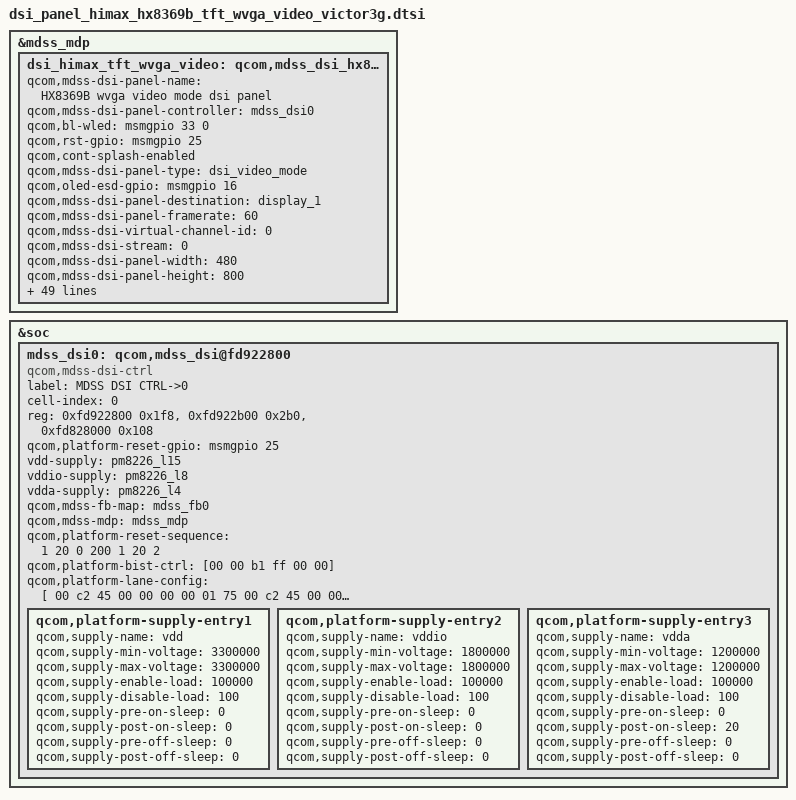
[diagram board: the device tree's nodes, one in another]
/* Copyright (c) 2012, Samsung Electronics Corporation. All rights reserved.
 *
 * This program is free software; you can redistribute it and/or modify
 * it under the terms of the GNU General Public License version 2 and
 * only version 2 as published by the Free Software Foundation.
 *
 * This program is distributed in the hope that it will be useful,
 * but WITHOUT ANY WARRANTY; without even the implied warranty of
 * MERCHANTABILITY or FITNESS FOR A PARTICULAR PURPOSE.  See the
 * GNU General Public License for more details.
 */

&mdss_mdp {

	dsi_himax_tft_wvga_video: qcom,mdss_dsi_hx8369b_wvga_video {
		qcom,mdss-dsi-panel-name = "HX8369B wvga video mode dsi panel";
		qcom,mdss-dsi-panel-controller = <&mdss_dsi0>;
		qcom,bl-wled = <&msmgpio 33 0>;
                qcom,rst-gpio = <&msmgpio 25 0>;
                qcom,cont-splash-enabled;
		qcom,mdss-dsi-panel-type = "dsi_video_mode";
		qcom,oled-esd-gpio = <&msmgpio 16 0>;
		qcom,mdss-dsi-panel-destination = "display_1";
		qcom,mdss-dsi-panel-framerate = <60>;
		qcom,mdss-dsi-virtual-channel-id = <0>;
		qcom,mdss-dsi-stream = <0>;
		qcom,mdss-dsi-panel-width = <480>;
		qcom,mdss-dsi-panel-height = <800>;
                qcom,mdss-pan-physical-width-dimension = <60>; /* <Width> real size of panel in mm */
		qcom,mdss-pan-physical-height-dimension = <100>; /*<Height> real size of panel in mm */
		qcom,mdss-dsi-lp11-init;
		qcom,mdss-dsi-init-delay-us = <100>;
		qcom,mdss-dsi-h-front-porch = <146>;
		qcom,mdss-dsi-h-back-porch = <136>;
		qcom,mdss-dsi-h-pulse-width = <60>;
		qcom,mdss-dsi-h-sync-skew = <0>;
		qcom,mdss-dsi-v-back-porch = <9>;
		qcom,mdss-dsi-v-front-porch = <10>;
		qcom,mdss-dsi-v-pulse-width = <6>;
		qcom,mdss-dsi-h-left-border = <0>;
		qcom,mdss-dsi-h-right-border = <0>;
		qcom,mdss-dsi-v-top-border = <0>;
		qcom,mdss-dsi-v-bottom-border = <0>;
		qcom,mdss-dsi-bpp = <24>;
		qcom,mdss-dsi-color-order = <0>;
		qcom,mdss-dsi-underflow-color = <0xff>;
		qcom,mdss-dsi-border-color = <0>;
		qcom,mdss-dsi-mdp-trigger = <0x0>;
		qcom,mdss-dsi-dma-trigger = <0x04>;
		qcom,mdss-dsi-bl-min-level = <1>;
		qcom,mdss-dsi-bl-max-level = <255>;
		qcom,mdss-dsi-bl-pmic-control-type = "bl_ctrl_pwm";
		qcom,mdss-pan-dsi-t-clk-pre = <0x18>;
		qcom,mdss-pan-dsi-t-clk-post = <0x04>;
		qcom,mdss-dsi-lane-0-state;
		qcom,mdss-dsi-lane-1-state;
		qcom,mdss-dsi-bllp-eof-power-mode;
		qcom,mdss-dsi-bllp-power-mode;
		qcom,mdss-dsi-traffic-mode = <2>;
		qcom,mdss-force-clk-lane-hs = <1>;
		qcom,mdss-dsi-lane-map = <5>;
		qcom,mdss-dsi-h-sync-pulse = <0>;
		qcom,mdss-dsi-panel-clock-rate = <489000000>;		
                qcom,mdss-dsi-panel-timings = [33 1E 14 00 44 48 18 22 19 03 04 00];
		qcom,platform-strength-ctrl = [ff 06];
		qcom,platform-regulator-settings = [07 08 07 00 20 07 01];
		qcom,mdss-dsi-on-command = [39 01 00 00 01 00 04 B9 FF 83 69
					39 01 00 00 0A 00 10 BA 31 00 16 CA B1 0A 00 10 28 02 21 21 9A 1A 8F
					39 01 00 00 01 00 02 3A 70
					39 01 00 00 01 00 5D D5 
					00 00 01 00 03 00 00 18 01 00 00 00 01 60 37 
					00 00 03 07 08 47 00 00 00 60 00 00 00 00 00
					00 00 03 00 00 10 00 00 91 13 35 57 75 18 00 
					00 00 86 64 42 20 00 49 00 00 00 90 02 24 46 
					64 08 00 00 00 87 75 53 31 11 59 00 00 00 00 
					01 00 00 00 0F 00 0F FF FF 0F 00 0F FF FF 00 
					85 5A
					39 01 00 00 01 00 0B B1 0B 83 77 00 0F 0F 17 17 0C 1A
					39 01 00 00 01 00 05 B3 83 00 31 03
               				39 01 00 00 01 00 02 B4 00
               				39 01 00 00 01 00 02 CB 6D
					39 01 00 00 01 00 02 CC 0E
					39 01 00 00 01 00 02 C1 00
					39 01 00 00 01 00 05 C6 41 FF 7A FF
					39 01 00 00 01 00 02 EA 72
					39 01 00 00 01 00 05 E3 07 0F 07 0F
               				39 01 00 00 78 00 07 C0 73 50 00 34 C4 09
               				39 01 00 00 01 00 24 E0 01 0E 12 29 2D 30 1E 3B 08 0D 0F 13 15 13 14 10 16 01 0E 11 2A 2D 30 1D 3B 08 0D 0F 13 15
                                        13 14 0F 16 01
               				05 01 00 00 B4 00 02 11 00
					05 01 00 00 01 00 02 29 00
	/* Display On */
					];
		samsung,panel-manufacture-id-read-cmds = [06 01 00 00 00 00 01 da 01
							06 01 00 00 00 00 01 db 01
							06 01 00 00 00 00 01 dc 01];

		qcom,mdss-dsi-on-command-state = "dsi_lp_mode";
		qcom,mdss-dsi-off-command = [05 01 00 00 32 00 02 28 00
					05 01 00 00 78 00 02 10 00];
		qcom,mdss-dsi-off-command-state = "dsi_hs_mode";
	};
};

&soc {
	mdss_dsi0: qcom,mdss_dsi@fd922800 {
		compatible = "qcom,mdss-dsi-ctrl";
		label = "MDSS DSI CTRL->0";
		cell-index = <0>;
		reg = 	<0xfd922800 0x1f8>,
			<0xfd922b00 0x2b0>,
			<0xfd828000 0x108>;
		reg-names = "dsi_ctrl", "dsi_phy", "mmss_misc_phys";
		qcom,platform-reset-gpio = <&msmgpio 25 0>;
		vdd-supply = <&pm8226_l15>;
		vddio-supply = <&pm8226_l8>;
		vdda-supply = <&pm8226_l4>;
		qcom,mdss-fb-map = <&mdss_fb0>;
		qcom,mdss-mdp = <&mdss_mdp>;
		qcom,platform-reset-sequence = <1 20 0 200 1 20 2>;
		qcom,platform-bist-ctrl = [00 00 b1 ff 00 00];
		qcom,platform-lane-config = [
			00 c2 45 00 00 00 00 01 75 /* lane0 config */
			00 c2 45 00 00 00 00 01 75 /* lane1 config */
			00 c2 45 00 00 00 00 01 75 /* lane2 config */
			00 c2 45 00 00 00 00 01 75 /* lane3 config */
			00 02 45 00 00 00 00 01 97]; /* Clk ln config */
		qcom,platform-supply-entry1 {
			qcom,supply-name = "vdd";
			qcom,supply-min-voltage = <3300000>;
			qcom,supply-max-voltage = <3300000>;
			qcom,supply-enable-load = <100000>;
			qcom,supply-disable-load = <100>;
			qcom,supply-pre-on-sleep = <0>;
			qcom,supply-post-on-sleep = <0>;
			qcom,supply-pre-off-sleep = <0>;
			qcom,supply-post-off-sleep = <0>;
		};
		qcom,platform-supply-entry2 {
			qcom,supply-name = "vddio";
			qcom,supply-min-voltage = <1800000>;
			qcom,supply-max-voltage = <1800000>;
			qcom,supply-enable-load = <100000>;
			qcom,supply-disable-load = <100>;
			qcom,supply-pre-on-sleep = <0>;
			qcom,supply-post-on-sleep = <0>;
			qcom,supply-pre-off-sleep = <0>;
			qcom,supply-post-off-sleep = <0>;
		};
		qcom,platform-supply-entry3 {
			qcom,supply-name = "vdda";
			qcom,supply-min-voltage = <1200000>;
			qcom,supply-max-voltage = <1200000>;
			qcom,supply-enable-load = <100000>;
			qcom,supply-disable-load = <100>;
			qcom,supply-pre-on-sleep = <0>;
			qcom,supply-post-on-sleep = <20>;
			qcom,supply-pre-off-sleep = <0>;
			qcom,supply-post-off-sleep = <0>;
		};
	};
};
